VERSION ""

NS_ :

BS_:

BU_:

BO_ 14 lin_vel_xy: 8 Vector__XXX
	SG_ lin_vel_x : 0|32@1+ (1,0) [0|0] "m/s" Vector__XXX
	SG_ lin_vel_y : 32|32@1+ (1,0) [0|0] "m/s" Vector__XXX

BO_ 11 imu_gyro_xy: 8 Vector__XXX
	SG_ gyro_x : 0|32@1+ (1,0) [0|0] "rad/s" Vector__XXX
	SG_ gyro_y : 32|32@1+ (1,0) [0|0] "rad/s" Vector__XXX

BO_ 12 imu_accel_xy: 8 Vector__XXX
	SG_ accel_x : 0|32@1+ (1,0) [0|0] "m/s^2" Vector__XXX
	SG_ accel_y : 32|32@1+ (1,0) [0|0] "m/s^2" Vector__XXX

BO_ 13 imu_z: 8 Vector__XXX
	SG_ gyro_z : 0|32@1+ (1,0) [0|0] "rad/s" Vector__XXX
	SG_ accel_z : 32|32@1+ (1,0) [0|0] "m/s^2" Vector__XXX

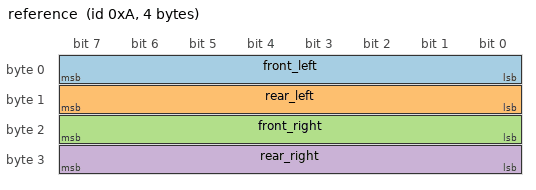
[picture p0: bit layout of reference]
BO_ 10 reference: 4 Vector__XXX
	SG_ front_left : 0|8@1+ (1,0) [0|0] "rpm" Vector__XXX
	SG_ rear_left : 8|8@1+ (1,0) [0|0] "rpm" Vector__XXX
	SG_ front_right : 16|8@1+ (1,0) [0|0] "rpm" Vector__XXX
	SG_ rear_right : 24|8@1+ (1,0) [0|0] "rpm" Vector__XXX

BA_DEF_ BO_  "VFrameFormat" ENUM  "StandardCAN","ExtendedCAN","reserved","J1939PG";
BA_DEF_  "DatabaseVersion" STRING ;
BA_DEF_  "BusType" STRING ;
BA_DEF_  "ProtocolType" STRING ;
BA_DEF_  "DatabaseCompiler" STRING ;
BA_DEF_DEF_  "VFrameFormat" "J1939PG";
BA_DEF_DEF_  "DatabaseVersion" "DEMO PLUS";
BA_DEF_DEF_  "BusType" "";
BA_DEF_DEF_  "ProtocolType" "";
BA_DEF_DEF_  "DatabaseCompiler" "";
BA_ "ProtocolType" "J1939";
BA_ "BusType" "CAN";
BA_ "DatabaseCompiler" "CSS ELECTRONICS (WWW.CSSELECTRONICS.COM)";
BA_ "DatabaseVersion" "1.0.0";
